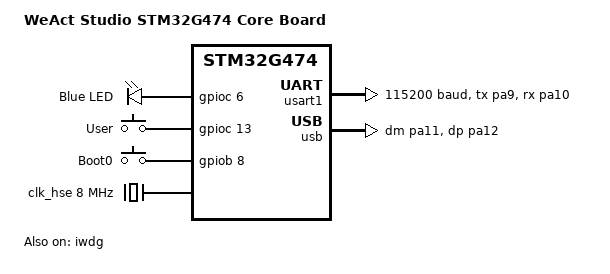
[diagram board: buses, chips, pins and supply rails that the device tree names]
/*
 * Copyright (c) 2026 John Crispin <john@phrozen.org>
 *
 * SPDX-License-Identifier: Apache-2.0
 */

/dts-v1/;
#include <st/g4/stm32g474Xe.dtsi>
#include <st/g4/stm32g474c(b-c-e)ux-pinctrl.dtsi>
#include <zephyr/dt-bindings/input/input-event-codes.h>

/ {
	model = "WeAct Studio STM32G474 Core Board";
	compatible = "weact,stm32g474-core";

	chosen {
		zephyr,console = &usart1;
		zephyr,shell-uart = &usart1;
		zephyr,sram = &sram0;
		zephyr,flash = &flash0;
	};

	aliases {
		led0 = &led_0;
		mcuboot-button0 = &button_0;
		mcuboot-led0 = &led_0;
		sw0 = &button_0;
		sw1 = &button_1;
		watchdog0 = &iwdg;
	};

	leds {
		compatible = "gpio-leds";
		led_0: led0 {
			gpios = <&gpioc 6 GPIO_ACTIVE_HIGH>;
			label = "Blue LED";
		};
	};

	gpio_keys {
		compatible = "gpio-keys";
		button_0: button0 {
			label = "User";
			gpios = <&gpioc 13 (GPIO_PULL_DOWN | GPIO_ACTIVE_HIGH)>;
			zephyr,code = <INPUT_KEY_0>;
		};
		button_1: button1 {
			label = "Boot0";
			gpios = <&gpiob 8 GPIO_ACTIVE_HIGH>;
			zephyr,code = <INPUT_KEY_1>;
		};
	};
};

&clk_hsi {
	status = "disabled";
};

&clk_hse {
	status = "okay";
	clock-frequency = <DT_FREQ_M(8)>;
};

&pll {
	status = "okay";
	div-m = <2>;
	mul-n = <72>;
	div-p = <2>;
	div-q = <6>;
	div-r = <2>;
	clocks = <&clk_hse>;
};

&rcc {
	clocks = <&pll>;
	clock-frequency = <DT_FREQ_M(144)>;
	ahb-prescaler = <1>;
	apb1-prescaler = <1>;
	apb2-prescaler = <1>;
};

&iwdg {
	status = "okay";
};

&usart1 {
	status = "okay";
	pinctrl-0 = <&usart1_tx_pa9 &usart1_rx_pa10>;
	pinctrl-names = "default";
	current-speed = <115200>;
};

zephyr_udc0: &usb {
	pinctrl-0 = <&usb_dm_pa11 &usb_dp_pa12>;
	pinctrl-names = "default";
	clocks = <&rcc STM32_CLOCK_BUS_APB1 0x00800000>,
		 <&rcc STM32_SRC_PLL_Q CLK48_SEL(2)>;
	status = "okay";
};
